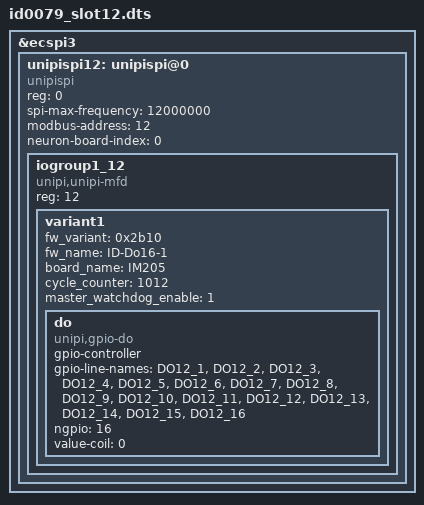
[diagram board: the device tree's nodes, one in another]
/dts-v1/;


/plugin/;

/ {
	fragment@1 {
		
		target = <&ecspi3>;
		__overlay__ {
			status = "okay";
			#address-cells = <1>;
			#size-cells = <0>;

			unipispi12: unipispi@0 {
				compatible = "unipispi";
				reg = <0>;
				status = "okay";
				spi-max-frequency = <12000000>;
				modbus-address = <12>;
				neuron-board-index = <0>;
			};
		};

	};

	fragment@2 {
		target = <&unipispi12>;
		__overlay__ {
			#address-cells = <1>;
			#size-cells = <0>;

			iogroup1_12 {
				reg = <12>;
				compatible = "unipi,unipi-mfd", "iogroup";
				variant1 { 
					fw_variant = <0x2b10>;
					fw_name = "ID-Do16-1";
					board_name = "IM205";
					cycle_counter = <1012>;
					master_watchdog_enable = <1>;

					do {
						compatible = "unipi,gpio-do";
						gpio-controller;
						#gpio-cells = <2>;
						gpio-line-names = "DO12_1", "DO12_2" , "DO12_3", "DO12_4", "DO12_5", "DO12_6", "DO12_7", "DO12_8", "DO12_9", "DO12_10", "DO12_11", "DO12_12", "DO12_13", "DO12_14", "DO12_15", "DO12_16";
						ngpio = <16>;
						value-coil = <0>;
					};
				};
			};
		};
	};
};
